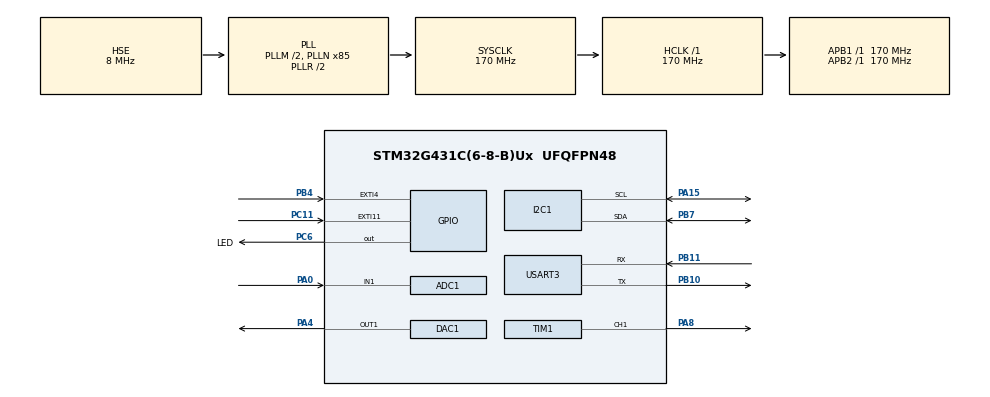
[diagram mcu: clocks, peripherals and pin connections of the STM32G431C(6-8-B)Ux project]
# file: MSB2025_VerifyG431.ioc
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ADC1.Channel-0\#ChannelRegularConversion=ADC_CHANNEL_1
ADC1.ClockPrescaler=ADC_CLOCK_ASYNC_DIV4
ADC1.ContinuousConvMode=ENABLE
ADC1.NbrOfConversionFlag=1
ADC1.OffsetNumber-0\#ChannelRegularConversion=ADC_OFFSET_NONE
ADC1.Rank-0\#ChannelRegularConversion=1
ADC1.SamplingTime-0\#ChannelRegularConversion=ADC_SAMPLETIME_47CYCLES_5
ADC1.master=1
DAC1.DAC_DMADoubleDataMode-DAC_OUT1=DISABLE
DAC1.DAC_HighFrequency_OUT1-DAC_OUT1=DAC_HIGH_FREQUENCY_INTERFACE_MODE_AUTOMATIC
DAC1.DAC_OutputBuffer-DAC_OUT1=DAC_OUTPUTBUFFER_ENABLE
DAC1.DAC_Trigger2_OUT1-DAC_OUT1=DAC_TRIGGER_NONE
DAC1.DAC_Trigger_OUT1-DAC_OUT1=DAC_TRIGGER_T6_TRGO
DAC1.WaveGeneration_OUT1-DAC_OUT1=DISABLE
Dma.ADC1.0.Direction=DMA_PERIPH_TO_MEMORY
Dma.ADC1.0.EventEnable=DISABLE
Dma.ADC1.0.Instance=DMA1_Channel1
Dma.ADC1.0.MemDataAlignment=DMA_MDATAALIGN_HALFWORD
Dma.ADC1.0.MemInc=DMA_MINC_ENABLE
Dma.ADC1.0.Mode=DMA_CIRCULAR
Dma.ADC1.0.PeriphDataAlignment=DMA_PDATAALIGN_HALFWORD
Dma.ADC1.0.PeriphInc=DMA_PINC_DISABLE
Dma.ADC1.0.Polarity=HAL_DMAMUX_REQ_GEN_RISING
Dma.ADC1.0.Priority=DMA_PRIORITY_LOW
Dma.ADC1.0.RequestNumber=1
Dma.ADC1.0.SignalID=NONE
Dma.ADC1.0.SyncEnable=DISABLE
Dma.ADC1.0.SyncPolarity=HAL_DMAMUX_SYNC_NO_EVENT
Dma.ADC1.0.SyncRequestNumber=1
Dma.ADC1.0.SyncSignalID=NONE
Dma.DAC1_CH1.1.Direction=DMA_MEMORY_TO_PERIPH
Dma.DAC1_CH1.1.EventEnable=DISABLE
Dma.DAC1_CH1.1.Instance=DMA2_Channel1
Dma.DAC1_CH1.1.MemDataAlignment=DMA_MDATAALIGN_HALFWORD
Dma.DAC1_CH1.1.MemInc=DMA_MINC_ENABLE
Dma.DAC1_CH1.1.Mode=DMA_CIRCULAR
Dma.DAC1_CH1.1.PeriphDataAlignment=DMA_PDATAALIGN_WORD
Dma.DAC1_CH1.1.PeriphInc=DMA_PINC_DISABLE
Dma.DAC1_CH1.1.Polarity=HAL_DMAMUX_REQ_GEN_RISING
Dma.DAC1_CH1.1.Priority=DMA_PRIORITY_MEDIUM
Dma.DAC1_CH1.1.RequestNumber=1
Dma.DAC1_CH1.1.SignalID=NONE
Dma.DAC1_CH1.1.SyncEnable=DISABLE
Dma.DAC1_CH1.1.SyncPolarity=HAL_DMAMUX_SYNC_NO_EVENT
Dma.DAC1_CH1.1.SyncRequestNumber=1
Dma.DAC1_CH1.1.SyncSignalID=NONE
Dma.Request0=ADC1
Dma.Request1=DAC1_CH1
I2C1.Timing=0x30A0A7FB
Mcu.Family=STM32G4
Mcu.Name=STM32G431C(6-8-B)Ux
Mcu.Package=UFQFPN48
NVIC.ADC1_2_IRQn=true\:3\:0\:true\:false\:true\:true\:true\:true
NVIC.DMA1_Channel1_IRQn=true\:3\:0\:true\:false\:true\:false\:true\:true
NVIC.DMA2_Channel1_IRQn=true\:3\:0\:true\:false\:true\:false\:true\:true
NVIC.EXTI15_10_IRQn=true\:4\:0\:true\:false\:true\:true\:true\:true
NVIC.EXTI4_IRQn=true\:4\:0\:true\:false\:true\:true\:true\:true
NVIC.PriorityGroup=NVIC_PRIORITYGROUP_4
NVIC.TIM6_DAC_IRQn=true\:3\:0\:true\:false\:true\:true\:true\:true
PA0.Mode=IN1-Single-Ended
PA0.Signal=ADC1_IN1
PA13.Mode=Serial_Wire
PA13.Signal=SYS_JTMS-SWDIO
PA14.Mode=Serial_Wire
PA14.Signal=SYS_JTCK-SWCLK
PA15.Mode=I2C
PA15.Signal=I2C1_SCL
PA4.Signal=COMP_DAC11_group
PA8.Signal=S_TIM1_CH1
PB10.Mode=Asynchronous
PB10.Signal=USART3_TX
PB11.Mode=Asynchronous
PB11.Signal=USART3_RX
PB4.GPIO_PuPd=GPIO_PULLUP
PB4.Signal=GPXTI4
PB7.Mode=I2C
PB7.Signal=I2C1_SDA
PC11.GPIO_PuPd=GPIO_PULLUP
PC11.Signal=GPXTI11
PC14-OSC32_IN.Mode=LSE-External-Oscillator
PC14-OSC32_IN.Signal=RCC_OSC32_IN
PC15-OSC32_OUT.Mode=LSE-External-Oscillator
PC15-OSC32_OUT.Signal=RCC_OSC32_OUT
PC6.GPIO_Label=LED
PC6.Signal=GPIO_Output
PF0-OSC_IN.Mode=HSE-External-Oscillator
PF0-OSC_IN.Signal=RCC_OSC_IN
PF1-OSC_OUT.Mode=HSE-External-Oscillator
PF1-OSC_OUT.Signal=RCC_OSC_OUT
ProjectManager.HeapSize=0x200
ProjectManager.StackSize=0x400
ProjectManager.TargetToolchain=MDK-ARM V5.32
RCC.ADC12CLockSelection=RCC_ADC12CLKSOURCE_PLL
RCC.ADC12Freq_Value=56666666.666666664
RCC.AHBFreq_Value=170000000
RCC.APB1Freq_Value=170000000
RCC.APB1TimFreq_Value=170000000
RCC.APB2Freq_Value=170000000
RCC.APB2TimFreq_Value=170000000
RCC.CortexFreq_Value=170000000
RCC.EXTERNAL_CLOCK_VALUE=12288000
RCC.HCLKFreq_Value=170000000
RCC.HSE_VALUE=8000000
RCC.HSI48_VALUE=48000000
RCC.HSI_VALUE=16000000
RCC.PLLM=RCC_PLLM_DIV2
RCC.PLLN=85
RCC.PLLP=RCC_PLLP_DIV6
RCC.PLLSourceVirtual=RCC_PLLSOURCE_HSE
RCC.SYSCLKFreq_VALUE=170000000
RCC.SYSCLKSource=RCC_SYSCLKSOURCE_PLLCLK
RCC.USBFreq_Value=170000000
RCC.VCOOutputFreq_Value=340000000
SH.COMP_DAC11_group.0=DAC1_OUT1,DAC_OUT1
SH.S_TIM1_CH1.0=TIM1_CH1,PWM Generation1 CH1
TIM1.Channel-PWM\ Generation1\ CH1=TIM_CHANNEL_1
TIM1.PeriodNoDither=100 - 1
TIM1.Prescaler=17 -  1
TIM1.PulseNoDither_1=50
TIM6.AutoReloadPreload=TIM_AUTORELOAD_PRELOAD_ENABLE
TIM6.PeriodNoDither=170  - 1
TIM6.Prescaler=0
TIM6.TIM_MasterOutputTrigger=TIM_TRGO_UPDATE
USART3.VirtualMode-Asynchronous=VM_ASYNC
VP_SYS_VS_DBSignals.Mode=DisableDeadBatterySignals
VP_TIM6_VS_ClockSourceINT.Mode=Enable_Timer
board=custom

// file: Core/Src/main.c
/* USER CODE BEGIN Header */
/**
  ******************************************************************************
  * @file           : main.c
  * @brief          : Main program body
  ******************************************************************************
  * @attention
  *
  * Copyright (c) 2025 STMicroelectronics.
  * All rights reserved.
  *
  * This software is licensed under terms that can be found in the LICENSE file
  * in the root directory of this software component.
  * If no LICENSE file comes with this software, it is provided AS-IS.
  *
  ******************************************************************************
  */
/* USER CODE END Header */
#include "main.h"
#include "adc.h"
#include "dac.h"
#include "dma.h"
#include "i2c.h"
#include "tim.h"
#include "usart.h"
#include "gpio.h"

/* USER CODE BEGIN Includes */
#include "tasks.h"
#include "dds.h"
#include "ui.h"
/* USER CODE END Includes */

void SystemClock_Config(void);

int main(void)
{

  /* MCU Configuration--------------------------------------------------------*/

  /* Reset of all peripherals, Initializes the Flash interface and the Systick. */
  HAL_Init();

  /* Configure the system clock */
  SystemClock_Config();

  /* Initialize all configured peripherals */
  MX_GPIO_Init();
  MX_DMA_Init();
  MX_ADC1_Init();
  MX_I2C1_Init();
  MX_DAC1_Init();
  MX_TIM1_Init();
  MX_TIM6_Init();
  MX_USART3_UART_Init();
  /* USER CODE BEGIN 2 */
  UI_Init();
  // DDS_Init();
  // DDS_Reload(99000, 3.0f); // 10kHz, 3Vpp
  // startup();
  // HAL_TIM_Base_Start(&htim1);
  // HAL_TIM_PWM_Start(&htim1, TIM_CHANNEL_1);
  /* USER CODE END 2 */

  /* Infinite loop */
  while (1)
  {

    /* USER CODE BEGIN 3 */
    UI_Update();
    HAL_Delay(100);
  }
  /* USER CODE END 3 */
}

void SystemClock_Config(void)
{
  RCC_OscInitTypeDef RCC_OscInitStruct = {0};
  RCC_ClkInitTypeDef RCC_ClkInitStruct = {0};

  /** Configure the main internal regulator output voltage
  */
  HAL_PWREx_ControlVoltageScaling(PWR_REGULATOR_VOLTAGE_SCALE1_BOOST);

  /** Initializes the RCC Oscillators according to the specified parameters
  * in the RCC_OscInitTypeDef structure.
  */
  RCC_OscInitStruct.OscillatorType = RCC_OSCILLATORTYPE_HSE;
  RCC_OscInitStruct.HSEState = RCC_HSE_ON;
  RCC_OscInitStruct.PLL.PLLState = RCC_PLL_ON;
  RCC_OscInitStruct.PLL.PLLSource = RCC_PLLSOURCE_HSE;
  RCC_OscInitStruct.PLL.PLLM = RCC_PLLM_DIV2;
  RCC_OscInitStruct.PLL.PLLN = 85;
  RCC_OscInitStruct.PLL.PLLP = RCC_PLLP_DIV6;
  RCC_OscInitStruct.PLL.PLLQ = RCC_PLLQ_DIV2;
  RCC_OscInitStruct.PLL.PLLR = RCC_PLLR_DIV2;
  if (HAL_RCC_OscConfig(&RCC_OscInitStruct) != HAL_OK)
  {
    Error_Handler();
  }

  /** Initializes the CPU, AHB and APB buses clocks
  */
  RCC_ClkInitStruct.ClockType = RCC_CLOCKTYPE_HCLK|RCC_CLOCKTYPE_SYSCLK
                              |RCC_CLOCKTYPE_PCLK1|RCC_CLOCKTYPE_PCLK2;
  RCC_ClkInitStruct.SYSCLKSource = RCC_SYSCLKSOURCE_PLLCLK;
  RCC_ClkInitStruct.AHBCLKDivider = RCC_SYSCLK_DIV1;
  RCC_ClkInitStruct.APB1CLKDivider = RCC_HCLK_DIV1;
  RCC_ClkInitStruct.APB2CLKDivider = RCC_HCLK_DIV1;

  if (HAL_RCC_ClockConfig(&RCC_ClkInitStruct, FLASH_LATENCY_4) != HAL_OK)
  {
    Error_Handler();
  }
}

void Error_Handler(void)
{
  __disable_irq();
  while (1)
  {
  }
}
